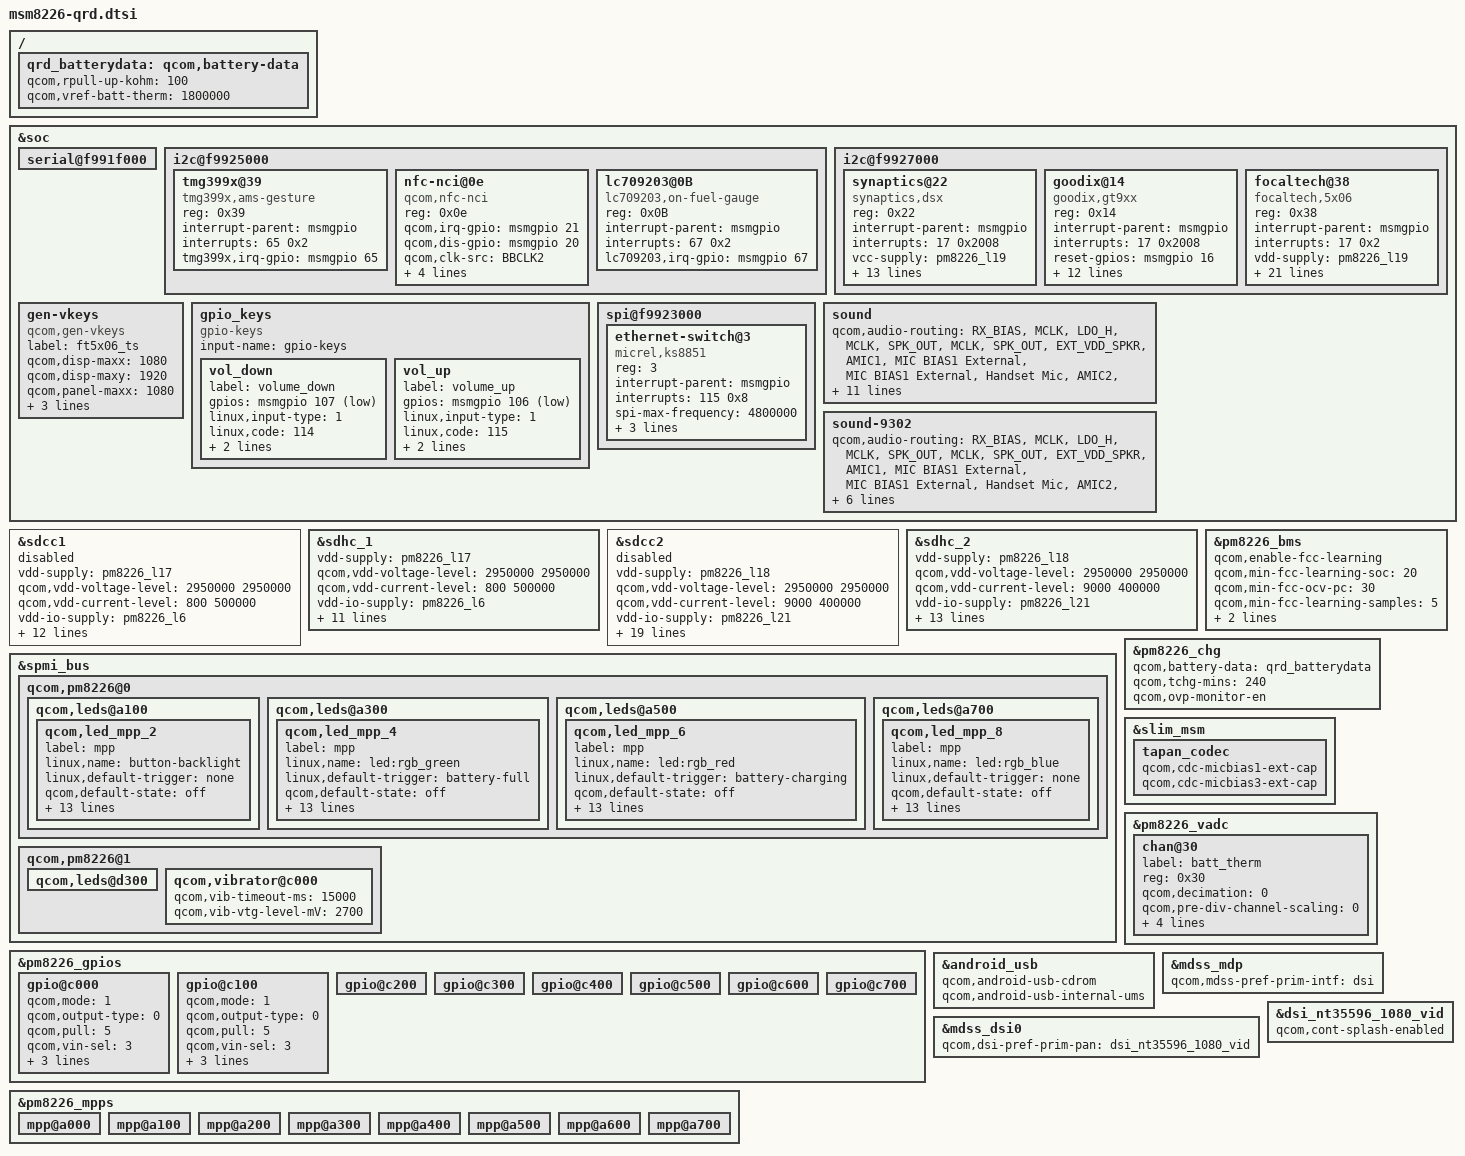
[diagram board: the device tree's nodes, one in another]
/* Copyright (c) 2013, The Linux Foundation. All rights reserved.
 *
 * This program is free software; you can redistribute it and/or modify
 * it under the terms of the GNU General Public License version 2 and
 * only version 2 as published by the Free Software Foundation.
 *
 * This program is distributed in the hope that it will be useful,
 * but WITHOUT ANY WARRANTY; without even the implied warranty of
 * MERCHANTABILITY or FITNESS FOR A PARTICULAR PURPOSE.  See the
 * GNU General Public License for more details.
 */

/include/ "msm8226-camera-sensor-qrd.dtsi"

&soc {
	serial@f991f000 {
		status = "ok";
	};

/** ZTE_MODIFY gongyahui port the driver code to P862A10 **/	
	i2c@f9925000 { /* BLSP1 QUP0 */
		tmg399x@39 {
			compatible = "tmg399x,ams-gesture";
			reg = <0x39>;
			interrupt-parent = <&msmgpio>;
			interrupts = <65 0x2>;
			tmg399x,irq-gpio = <&msmgpio 65 0x2>;
		};
/** ZTE_MODIFY end **/		
	};	

	
        i2c@f9925000 { /* BLSP1 QUP3 */
                nfc-nci@0e {
                        compatible = "qcom,nfc-nci";
                        reg = <0x0e>;
                        qcom,irq-gpio = <&msmgpio 21 0x00>;
                        qcom,dis-gpio = <&msmgpio 20 0x00>;
                        qcom,clk-src = "BBCLK2";
                        qcom,clk-en-gpio = <&msmgpio 0 0x00>;
                        interrupt-parent = <&msmgpio>;
                        interrupts = <21 0>;
                        qcom,clk-gpio = <&pm8226_gpios 3 0>;
                };

                /** ZTE_MODIFY end **/
	         lc709203@0B {
			compatible = "lc709203,on-fuel-gauge";
			reg = <0x0B>;
			interrupt-parent = <&msmgpio>;
			interrupts = <67 0x2>;
			lc709203,irq-gpio = <&msmgpio 67 0x2>;
		  };
        };

/** ZTE_MODIFY niugang10089953 port the driver code to P862A10 **/	
	i2c@f9927000 { /* BLSP1 QUP5 */
		synaptics@22 {
			compatible = "synaptics,dsx";
			reg = <0x22>;
			interrupt-parent = <&msmgpio>;
			interrupts = <17 0x2008>;
			vcc-supply = <&pm8226_l19>;
			synaptics,reg-en;
			vcc_i2c-supply = <&pm8226_lvs1>;
			synaptics,i2c-pull-up;
			synaptics,reset-gpio = <&msmgpio 16 0x00>;
			synaptics,irq-gpio = <&msmgpio 17 0x2008>;
			synaptics,x-flip = <0>;
			synaptics,y-flip = <0>;
			synaptics,power-on-status = <1>;
			synaptics,reset-on-status = <0>;
			synaptics,power-delay-ms = <160>;
			synaptics,reset-delay-ms = <250>;
			synaptics,reset-active-ms = <20>;
			synaptics,button-map = <139 102 158>;
		};
		goodix@14 {
			compatible = "goodix,gt9xx";
			reg = <0x14>;
			interrupt-parent = <&msmgpio>;
			interrupts = <17 0x2008>;
			reset-gpios = <&msmgpio 16 0x00>;
			interrupt-gpios = <&msmgpio 17 0x00>;
			vdd-supply = <&pm8226_l19>;
			vcc_i2c-supply = <&pm8226_lvs1>;
			goodix,panel-coords = <0 0 720 1200>;
			goodix,display-coords = <0 0 720 1080>;
			goodix,button-map= <139 172 158>;
			goodix,product-id = "615";
			goodix,cfg-data0 = [
				41 D0 02 00 05 05 35 C0 01 88
				23 5F 50 3C 03 05 00 00 00 00
				00 00 05 14 16 1C 14 8B 0A 0C 
				5A 5C CD 03 00 00 00 BA 03 1D 
				41 13 01 0F 0A 5A 64 30 24 00 
				0A 35 74 94 C5 02 08 00 00 04 
				C1 39 00 A6 43 00 91 4E 00 7E 
				5B 00 6D 6B 00 6D 00 00 00 00 
				00 00 00 00 00 00 00 00 00 00 
				00 00 00 00 00 00 00 00 00 00 
				00 46 00 1E 00 00 00 00 00 00 
				14 0A 18 16 14 12 10 0E 0C 0A 
				08 06 04 02 FF FF FF FF FF E7 
				FF FF FF 0F 00 00 00 00 00 00 
				00 00 1E 1F 1D 20 1C 21 18 22 
				16 24 13 00 12 02 10 04 0F 06 
				0C 08 0A FF FF FF FF FF 00 00 
				00 F3 FF FF FF FF FF FF FF FF 
				FF FE FF FF EF 01];
			goodix,cfg-data1 = [
				41 D0 02 00 05 05 35 C0 01 88
				23 5F 50 3C 03 05 00 00 00 00
				00 00 05 14 16 1C 14 8B 0A 0C 
				5A 5C CD 03 00 00 00 BA 03 1D 
				41 13 01 0F 0A 5A 64 30 24 00 
				0A 35 74 94 C5 02 08 00 00 04 
				C1 39 00 A6 43 00 91 4E 00 7E 
				5B 00 6D 6B 00 6D 00 00 00 00 
				00 00 00 00 00 00 00 00 00 00 
				00 00 00 00 00 00 00 00 00 00 
				00 46 00 1E 00 00 00 00 00 00 
				14 0A 18 16 14 12 10 0E 0C 0A 
				08 06 04 02 FF FF FF FF FF E7 
				FF FF FF 0F 00 00 00 00 00 00 
				00 00 1E 1F 1D 20 1C 21 18 22 
				16 24 13 00 12 02 10 04 0F 06 
				0C 08 0A FF FF FF FF FF 00 00 
				00 F3 FF FF FF FF FF FF FF FF 
				FF FE FF FF EF 01];
			goodix,fw_name = "gtp_fw.bin";
		};
/** ZTE_MODIFY end **/		

		focaltech@38 {
			compatible = "focaltech,5x06";
			reg = <0x38>;
			interrupt-parent = <&msmgpio>;
			interrupts = <17 0x2>;
			vdd-supply = <&pm8226_l19>;
			vcc_i2c-supply = <&pm8226_lvs1>;
			focaltech,name = "ft5x06";
			focaltech,family-id = <0x55>;
			focaltech,reset-gpio = <&msmgpio 16 0x00>;
			focaltech,irq-gpio = <&msmgpio 17 0x00>;
			focaltech,display-coords = <0 0 1080 1920>;
			focaltech,panel-coords = <0 0 1080 2000>;
			focaltech,button-map= <139 102 158>;
			focaltech,no-force-update;
			focaltech,i2c-pull-up;
			focaltech,group-id = <1>;
			focaltech,hard-reset-delay-ms = <20>;
			focaltech,soft-reset-delay-ms = <150>;
			focaltech,num-max-touches = <5>;
			focaltech,fw-name = "ft_8226_qrd_1080p_fw.bin";
			focaltech,fw-delay-aa-ms = <50>;
			focaltech,fw-delay-55-ms = <30>;
			focaltech,fw-upgrade-id1 = <0x79>;
			focaltech,fw-upgrade-id2 = <0x03>;
			focaltech,fw-delay-readid-ms = <10>;
			focaltech,fw-delay-era-flsh-ms = <2000>;
		};
	};

	gen-vkeys {
		compatible = "qcom,gen-vkeys";
		label = "ft5x06_ts";
		qcom,disp-maxx = <1080>;
		qcom,disp-maxy = <1920>;
		qcom,panel-maxx = <1080>;
		qcom,panel-maxy = <2080>;
		qcom,key-codes = <139 102 158>;
		qcom,y-offset = <0>;
	};

	gpio_keys {
		compatible = "gpio-keys";
		input-name = "gpio-keys";
		/** ZTE_MODIFY wangzhanmeng, del for gpio108 no using as camera_focus 20140405 **/
        /*	
		camera_focus {
			label = "camera_focus";
			gpios = <&msmgpio 108 0x1>;
			linux,input-type = <1>;
			linux,code = <0x210>;
			gpio-key,wakeup;
			debounce-interval = <15>;
		};
		*/
		/** ZTE_MODIFY wangzhanmeng, del for gpio108 no using as camera_focus end **/
		/** ZTE_MODIFY niugang10089953 modify for for vol_down key config **/
        /*	
		camera_snapshot {
			label = "camera_snapshot";
			gpios = <&msmgpio 107 0x1>;
			linux,input-type = <1>;
			linux,code = <0x2fe>;
			gpio-key,wakeup;
			debounce-interval = <15>;
		};
		*/
		vol_down {
			label = "volume_down";
			gpios = <&msmgpio 107 0x1>;
			linux,input-type = <1>;
			linux,code = <114>;
			gpio-key,wakeup;
			debounce-interval = <0>;
		};
		/** ZTE_MODIFY end **/

		vol_up {
			label = "volume_up";
			gpios = <&msmgpio 106 0x1>;
			linux,input-type = <1>;
			linux,code = <115>;
			gpio-key,wakeup;
			debounce-interval = <0>;
		};
	};

	spi@f9923000 {
		ethernet-switch@3 {
			compatible = "micrel,ks8851";
			reg = <3>;
			interrupt-parent = <&msmgpio>;
			interrupts = <115 0x8>;
			spi-max-frequency = <4800000>;
			rst-gpio = <&msmgpio 114 0>;
			vdd-io-supply = <&pm8226_lvs1>;
			vdd-phy-supply = <&pm8226_lvs1>;
		};
	};

	sound {
		qcom,audio-routing =
			"RX_BIAS", "MCLK",
			"LDO_H", "MCLK",
			"SPK_OUT", "MCLK",
			"SPK_OUT", "EXT_VDD_SPKR",
			"AMIC1", "MIC BIAS1 External",
			"MIC BIAS1 External", "Handset Mic",
			"AMIC2", "MIC BIAS2 External",
			"MIC BIAS2 External", "Headset Mic",
			"AMIC3", "MIC BIAS1 External",
			"MIC BIAS1 External", "Analog Mic3",
			"AMIC4", "MIC BIAS3 External",
			"MIC BIAS3 External", "Analog Mic4",
			"DMIC3", "MIC BIAS3 External",
			"MIC BIAS3 External", "Digital Mic3",
			"DMIC4", "MIC BIAS3 External",
			"MIC BIAS3 External", "Digital Mic4";

		qcom,cdc-mclk-gpios = <&pm8226_gpios 1 0>;
		qcom,cdc-vdd-spkr-gpios = <&pm8226_gpios 2 0>;
		qcom,cdc-us-euro-gpios = <&msmgpio 69 0>;
	};

	sound-9302 {
		qcom,audio-routing =
			"RX_BIAS", "MCLK",
			"LDO_H", "MCLK",
			"SPK_OUT", "MCLK",
			"SPK_OUT", "EXT_VDD_SPKR",
			"AMIC1", "MIC BIAS1 External",
			"MIC BIAS1 External", "Handset Mic",
			"AMIC2", "MIC BIAS2 External",
			"MIC BIAS2 External", "Headset Mic",
			"AMIC3", "MIC BIAS1 External",
			"MIC BIAS1 External", "Handset Mic";

		qcom,cdc-mclk-gpios = <&pm8226_gpios 1 0>;
		qcom,cdc-vdd-spkr-gpios = <&pm8226_gpios 2 0>;
		qcom,cdc-us-euro-gpios = <&msmgpio 69 0>;
	};
};

&sdcc1 {
	vdd-supply = <&pm8226_l17>;
	qcom,vdd-voltage-level = <2950000 2950000>;
	qcom,vdd-current-level = <800 500000>;

	vdd-io-supply = <&pm8226_l6>;
	qcom,vdd-io-always-on;
	qcom,vdd-io-voltage-level = <1800000 1800000>;
	qcom,vdd-io-current-level = <250 154000>;

	qcom,pad-pull-on = <0x0 0x3 0x3>; /* no-pull, pull-up, pull-up */
	qcom,pad-pull-off = <0x0 0x3 0x3>; /* no-pull, pull-up, pull-up */
	qcom,pad-drv-on = <0x4 0x4 0x4>; /* 10mA, 10mA, 10mA */
	qcom,pad-drv-off = <0x0 0x0 0x0>; /* 2mA, 2mA, 2mA */

	qcom,clk-rates = <400000 25000000 50000000 100000000 200000000>;
	qcom,sup-voltages = <2950 2950>;

	qcom,bus-speed-mode = "HS200_1p8v", "DDR_1p8v";
	qcom,nonremovable;

	status = "disabled";
};

&sdhc_1 {
	vdd-supply = <&pm8226_l17>;
	qcom,vdd-voltage-level = <2950000 2950000>;
	qcom,vdd-current-level = <800 500000>;

	vdd-io-supply = <&pm8226_l6>;
	qcom,vdd-io-always-on;
	qcom,vdd-io-voltage-level = <1800000 1800000>;
	qcom,vdd-io-current-level = <250 154000>;

	qcom,pad-pull-on = <0x0 0x3 0x3>; /* no-pull, pull-up, pull-up */
	qcom,pad-pull-off = <0x0 0x3 0x3>; /* no-pull, pull-up, pull-up */
	qcom,pad-drv-on = <0x4 0x4 0x4>; /* 10mA, 10mA, 10mA */
	qcom,pad-drv-off = <0x0 0x0 0x0>; /* 2mA, 2mA, 2mA */

	qcom,clk-rates = <400000 25000000 50000000 100000000 200000000>;
	qcom,bus-speed-mode = "HS200_1p8v", "DDR_1p8v";
	qcom,nonremovable;

	status = "ok";
};

&sdcc2 {
	vdd-supply = <&pm8226_l18>;
	qcom,vdd-voltage-level = <2950000 2950000>;
	qcom,vdd-current-level = <9000 400000>;

	vdd-io-supply = <&pm8226_l21>;
	qcom,vdd-io-voltage-level = <1800000 2950000>;
	qcom,vdd-io-current-level = <6 22000>;

	qcom,pad-pull-on = <0x0 0x3 0x3>; /* no-pull, pull-up, pull-up */
	qcom,pad-pull-off = <0x0 0x3 0x3>; /* no-pull, pull-up, pull-up */
	qcom,pad-drv-on = <0x4 0x4 0x4>; /* 10mA, 10mA, 10mA */
	qcom,pad-drv-off = <0x0 0x0 0x0>; /* 2mA, 2mA, 2mA */

	qcom,clk-rates = <400000 25000000 50000000 100000000 200000000>;
	qcom,sup-voltages = <2950 2950>;

	qcom,xpc;
	qcom,bus-speed-mode = "SDR12", "SDR25", "SDR50", "DDR50", "SDR104";
	qcom,current-limit = <400>;

	#address-cells = <0>;
	interrupt-parent = <&sdcc2>;
	interrupts = <0 1 2>;
	#interrupt-cells = <1>;
	interrupt-map-mask = <0xffffffff>;
	interrupt-map = <0 &intc 0 125 0
			1 &intc 0 220 0
			2 &msmgpio 38 0x3>;
	interrupt-names = "core_irq", "bam_irq", "status_irq";
	cd-gpios = <&msmgpio 38 0x1>;

	status = "disabled";
};

&sdhc_2 {
	vdd-supply = <&pm8226_l18>;
	qcom,vdd-voltage-level = <2950000 2950000>;
	qcom,vdd-current-level = <9000 400000>;

	vdd-io-supply = <&pm8226_l21>;
	qcom,vdd-io-voltage-level = <1800000 2950000>;
	qcom,vdd-io-current-level = <6 22000>;

	qcom,pad-pull-on = <0x0 0x3 0x3>; /* no-pull, pull-up, pull-up */
	qcom,pad-pull-off = <0x0 0x3 0x3>; /* no-pull, pull-up, pull-up */
	qcom,pad-drv-on = <0x4 0x4 0x4>; /* 10mA, 10mA, 10mA */
	qcom,pad-drv-off = <0x0 0x0 0x0>; /* 2mA, 2mA, 2mA */

	qcom,clk-rates = <400000 25000000 50000000>;

	#address-cells = <0>;
	interrupt-parent = <&sdhc_2>;
	interrupts = <0 1 2>;
	#interrupt-cells = <1>;
	interrupt-map-mask = <0xffffffff>;
	interrupt-map = <0 &intc 0 125 0
			1 &intc 0 221 0
			2 &msmgpio 38 0x3>;
	interrupt-names = "hc_irq", "pwr_irq", "status_irq";
	cd-gpios = <&msmgpio 38 0x1>;

	status = "ok";
};

&spmi_bus {
	qcom,pm8226@0 {
		qcom,leds@a100 {
			status = "okay";
			qcom,led_mpp_2 {
				label = "mpp";
				linux,name = "button-backlight";
				linux,default-trigger = "none";
				qcom,default-state = "off";
				qcom,max-current = <40>;
				qcom,current-setting = <5>;
				qcom,id = <6>;
				qcom,mode = "manual";
				qcom,source-sel = <1>;
				qcom,mode-ctrl = <0x60>;
				qcom,pwm-us = <1000>;
				qcom,pwm-channel = <3>;
				qcom,start-idx = <1>;
				qcom,ramp-step-ms = <120>;
				qcom,duty-pcts = [00 00 00 00 00
						  00 00 00 00 00
						  50 00 00 00 00
						  00 00 00 00 00
						  00];
				qcom,use-blink;
			};
		};

		qcom,leds@a300 {
			status = "okay";
			qcom,led_mpp_4 {
				label = "mpp";
				linux,name = "led:rgb_green";
				linux,default-trigger = "battery-full";
				qcom,default-state = "off";
				qcom,max-current = <40>;
				qcom,current-setting = <20>;
				qcom,id = <6>;
				qcom,mode = "pwm";
				qcom,pwm-us = <1000>;
				qcom,source-sel = <8>;
				qcom,mode-ctrl = <0x60>;
				qcom,pwm-channel = <0>;
				qcom,start-idx = <1>;
				qcom,ramp-step-ms = <120>;
				qcom,duty-pcts = [00 00 00 00 00
						  00 00 00 00 00
						  50 00 00 00 00
						  00 00 00 00 00
						  00];
				qcom,use-blink;
			};
		};

		qcom,leds@a500 {
			status = "okay";
			qcom,led_mpp_6 {
				label = "mpp";
				linux,name = "led:rgb_red";
				linux,default-trigger = "battery-charging";
				qcom,default-state = "off";
				qcom,max-current = <40>;
				qcom,current-setting = <20>;
				qcom,id = <6>;
				qcom,mode = "pwm";
				qcom,pwm-us = <1000>;
				qcom,mode-ctrl = <0x60>;
				qcom,source-sel = <10>;
				qcom,pwm-channel = <5>;
				qcom,start-idx = <1>;
				qcom,ramp-step-ms = <120>;
				qcom,duty-pcts = [00 00 00 00 00
						  00 00 00 00 00
						  50 00 00 00 00
						  00 00 00 00 00
						  00];
				qcom,use-blink;
			};
		};

		qcom,leds@a700 {
			status = "okay";
			qcom,led_mpp_8 {
				label = "mpp";
				linux,name = "led:rgb_blue";
				linux,default-trigger = "none";
				qcom,default-state = "off";
				qcom,max-current = <40>;
				qcom,current-setting = <20>;
				qcom,id = <6>;
				qcom,mode = "pwm";
				qcom,pwm-us = <1000>;
				qcom,mode-ctrl = <0x60>;
				qcom,source-sel = <20>;
				qcom,pwm-channel = <4>;
				qcom,start-idx = <1>;
				qcom,ramp-step-ms = <120>;
				qcom,duty-pcts = [00 00 00 00 00
						  00 00 00 00 00
						  50 00 00 00 00
						  00 00 00 00 00
						  00];
				qcom,use-blink;
			};
		};
	};

	qcom,pm8226@1 {
                qcom,leds@d300 {
                        status = "okay";
                };
/*
		qcom,leds@d800 {
			status = "okay";
			qcom,wled_0 {
				label = "wled";
				linux,name = "wled:backlight";
				linux,default-trigger = "bkl-trigger";
				qcom,cs-out-en;
				qcom,op-fdbck = <1>;
				qcom,default-state = "on";
				qcom,max-current = <20>;
				qcom,ctrl-delay-us = <0>;
				qcom,boost-curr-lim = <3>;
				qcom,cp-sel = <0>;
				qcom,switch-freq = <11>;
				qcom,ovp-val = <0>;
				qcom,num-strings = <1>;
				qcom,id = <0>;
			};
		};
*/
		qcom,vibrator@c000 {
			status = "okay";
			qcom,vib-timeout-ms = <15000>;
			qcom,vib-vtg-level-mV = <2700>;
		};

	};
};

/ {
	qrd_batterydata: qcom,battery-data {
		qcom,rpull-up-kohm = <100>;
		qcom,vref-batt-therm = <1800000>;

		/include/ "batterydata-qrd-4v35-2000mah.dtsi"
	};
};

&pm8226_bms {
	status = "okay";
	qcom,enable-fcc-learning;
	qcom,min-fcc-learning-soc = <20>;
	qcom,min-fcc-ocv-pc = <30>;
	qcom,min-fcc-learning-samples = <5>;
	qcom,fcc-resolution = <10>;
	qcom,battery-data = <&qrd_batterydata>;
};

&pm8226_chg {
	status = "okay";
	qcom,battery-data = <&qrd_batterydata>;
	qcom,tchg-mins = <240>;
	qcom,ovp-monitor-en;
};

&pm8226_gpios {
	gpio@c000 { /* GPIO 1 */
		/* XO_PMIC_CDC_MCLK enable for tapan codec */
		qcom,mode = <1>;		/* Digital output */
		qcom,output-type = <0>;	/* CMOS logic */
		qcom,pull = <5>;		/* QPNP_PIN_PULL_NO*/
		qcom,vin-sel = <3>;		/* QPNP_PIN_VIN3 */
		qcom,out-strength = <3>;/* QPNP_PIN_OUT_STRENGTH_HIGH */
		qcom,src-sel = <2>;		/* QPNP_PIN_SEL_FUNC_1 */
		qcom,master-en = <1>;	/* Enable GPIO */
	};

	gpio@c100 { /* GPIO 2 */
		qcom,mode = <1>;
		qcom,output-type = <0>;
		qcom,pull = <5>;
		qcom,vin-sel = <3>;
		qcom,out-strength = <3>;
		qcom,src-sel = <2>;
		qcom,master-en = <1>;
	};

	gpio@c200 { /* GPIO 3 */
	};

	gpio@c300 { /* GPIO 4 */
	};

	gpio@c400 { /* GPIO 5 */
	};

	gpio@c500 { /* GPIO 6 */
	};

	gpio@c600 { /* GPIO 7 */
	};

	gpio@c700 { /* GPIO 8 */
	};
};

&pm8226_mpps {
	mpp@a000 { /* MPP 1 */
	};

	mpp@a100 { /* MPP 2 */
	};

	mpp@a200 { /* MPP 3 */
	};

	mpp@a300 { /* MPP 4 */
	};

	mpp@a400 { /* MPP 5 */
	};

	mpp@a500 { /* MPP 6 */
	};

	mpp@a600 { /* MPP 7 */
	};

	mpp@a700 { /* MPP 8 */
	};
};

&slim_msm {
	tapan_codec {
		qcom,cdc-micbias1-ext-cap;
		qcom,cdc-micbias3-ext-cap;
	};
};

&pm8226_vadc {
	chan@30 {
		label = "batt_therm";
		reg = <0x30>;
		qcom,decimation = <0>;
		qcom,pre-div-channel-scaling = <0>;
		qcom,calibration-type = "ratiometric";
		qcom,scale-function = <6>;
		qcom,hw-settle-time = <2>;
		qcom,fast-avg-setup = <0>;
	};
};

&android_usb {
	qcom,android-usb-cdrom;
	qcom,android-usb-internal-ums;
};

&mdss_mdp {
	qcom,mdss-pref-prim-intf = "dsi";
/*	batfet-supply = <&pm8226_chg_batif>; */
};

&mdss_dsi0 {
	qcom,dsi-pref-prim-pan = <&dsi_nt35596_1080_vid>;
};

&dsi_nt35596_1080_vid {
	qcom,cont-splash-enabled;
};
